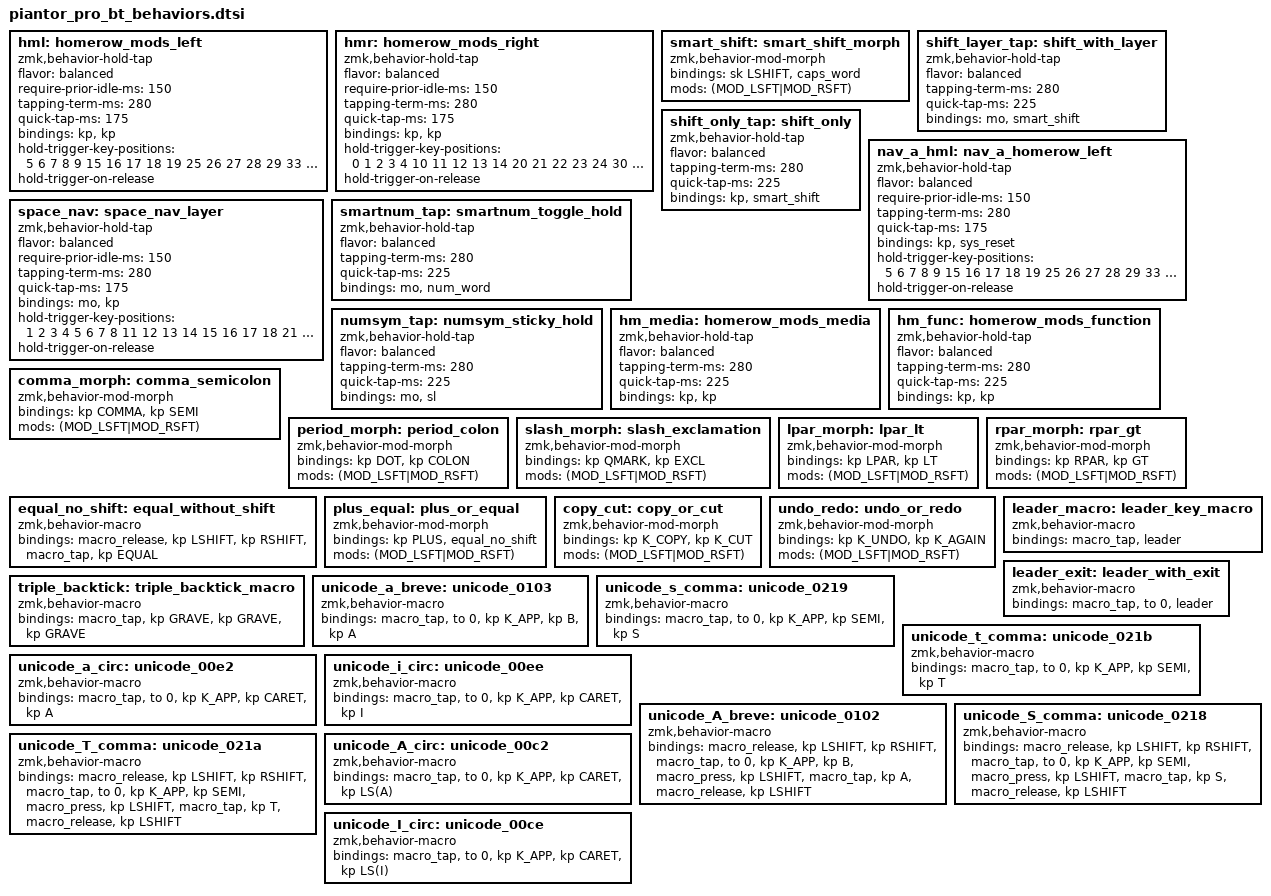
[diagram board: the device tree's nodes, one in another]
// Custom behaviors for Piantor Pro BT
hml: homerow_mods_left {
    compatible = "zmk,behavior-hold-tap";
    #binding-cells = <2>;
    flavor = "balanced";
    require-prior-idle-ms = <150>;
    tapping-term-ms = <280>;
    quick-tap-ms = <175>;
    bindings = <&kp>, <&kp>;
    hold-trigger-key-positions = <5 6 7 8 9 15 16 17 18 19 25 26 27 28 29 33 34 35>;
    hold-trigger-on-release;
};
hmr: homerow_mods_right {
    compatible = "zmk,behavior-hold-tap";
    #binding-cells = <2>;
    flavor = "balanced";
    require-prior-idle-ms = <150>;
    tapping-term-ms = <280>;
    quick-tap-ms = <175>;
    bindings = <&kp>, <&kp>;
    hold-trigger-key-positions = <0 1 2 3 4 10 11 12 13 14 20 21 22 23 24 30 31 32>;
    hold-trigger-on-release;
};
smart_shift: smart_shift_morph {
    compatible = "zmk,behavior-mod-morph";
    #binding-cells = <0>;
    bindings = <&sk LSHIFT>, <&caps_word>;
    mods = <(MOD_LSFT|MOD_RSFT)>;
};
shift_layer_tap: shift_with_layer {
    compatible = "zmk,behavior-hold-tap";
    #binding-cells = <2>;
    flavor = "balanced";
    tapping-term-ms = <280>;
    quick-tap-ms = <225>;
    bindings = <&mo>, <&smart_shift>;
};
shift_only_tap: shift_only {
    compatible = "zmk,behavior-hold-tap";
    #binding-cells = <2>;
    flavor = "balanced";
    tapping-term-ms = <280>;
    quick-tap-ms = <225>;
    bindings = <&kp>, <&smart_shift>;
};
// Nav layer position A: tap=reset, hold=alt (matches hml timing)
nav_a_hml: nav_a_homerow_left {
    compatible = "zmk,behavior-hold-tap";
    #binding-cells = <2>;
    flavor = "balanced";
    require-prior-idle-ms = <150>;
    tapping-term-ms = <280>;
    quick-tap-ms = <175>;
    bindings = <&kp>, <&sys_reset>;
    hold-trigger-key-positions = <5 6 7 8 9 15 16 17 18 19 25 26 27 28 29 33 34 35>;
    hold-trigger-on-release;
};
// Space nav layer: tap=space, hold=nav_sys layer (excludes dangerous positions)
space_nav: space_nav_layer {
    compatible = "zmk,behavior-hold-tap";
    #binding-cells = <2>;
    flavor = "balanced";
    require-prior-idle-ms = <150>;
    tapping-term-ms = <280>;
    quick-tap-ms = <175>;
    bindings = <&mo>, <&kp>;
    hold-trigger-key-positions = <1 2 3 4 5 6 7 8 11 12 13 14 15 16 17 18 21 22 23 24 25 26 27 28 30 31 32 33 34 35>;
    hold-trigger-on-release;
};
smartnum_tap: smartnum_toggle_hold {
    compatible = "zmk,behavior-hold-tap";
    #binding-cells = <2>;
    flavor = "balanced";
    tapping-term-ms = <280>;
    quick-tap-ms = <225>;
    bindings = <&mo>, <&num_word>;
};
numsym_tap: numsym_sticky_hold {
    compatible = "zmk,behavior-hold-tap";
    #binding-cells = <2>;
    flavor = "balanced";
    tapping-term-ms = <280>;
    quick-tap-ms = <225>;
    bindings = <&mo>, <&sl>;
};
#include "piantor_pro_bt_leader.dtsi"
// System layer media key home row mods
hm_media: homerow_mods_media {
    compatible = "zmk,behavior-hold-tap";
    #binding-cells = <2>;
    flavor = "balanced";
    tapping-term-ms = <280>;
    quick-tap-ms = <225>;
    bindings = <&kp>, <&kp>;
};
// System layer function key home row mods
hm_func: homerow_mods_function {
    compatible = "zmk,behavior-hold-tap";
    #binding-cells = <2>;
    flavor = "balanced";
    tapping-term-ms = <280>;
    quick-tap-ms = <225>;
    bindings = <&kp>, <&kp>;
};

// Custom shift behaviors for comma, period, slash
comma_morph: comma_semicolon {
    compatible = "zmk,behavior-mod-morph";
    #binding-cells = <0>;
    bindings = <&kp COMMA>, <&kp SEMI>;
    mods = <(MOD_LSFT|MOD_RSFT)>;
};
period_morph: period_colon {
    compatible = "zmk,behavior-mod-morph";
    #binding-cells = <0>;
    bindings = <&kp DOT>, <&kp COLON>;
    mods = <(MOD_LSFT|MOD_RSFT)>;
};
slash_morph: slash_exclamation {
    compatible = "zmk,behavior-mod-morph";
    #binding-cells = <0>;
    bindings = <&kp QMARK>, <&kp EXCL>;
    mods = <(MOD_LSFT|MOD_RSFT)>;
};
lpar_morph: lpar_lt {
    compatible = "zmk,behavior-mod-morph";
    #binding-cells = <0>;
    bindings = <&kp LPAR>, <&kp LT>;
    mods = <(MOD_LSFT|MOD_RSFT)>;
};
rpar_morph: rpar_gt {
    compatible = "zmk,behavior-mod-morph";
    #binding-cells = <0>;
    bindings = <&kp RPAR>, <&kp GT>;
    mods = <(MOD_LSFT|MOD_RSFT)>;
};
equal_no_shift: equal_without_shift {
    compatible = "zmk,behavior-macro";
    #binding-cells = <0>;
    bindings = <&macro_release &kp LSHIFT &kp RSHIFT>, <&macro_tap &kp EQUAL>;
};
plus_equal: plus_or_equal {
    compatible = "zmk,behavior-mod-morph";
    #binding-cells = <0>;
    bindings = <&kp PLUS>, <&equal_no_shift>;
    mods = <(MOD_LSFT|MOD_RSFT)>;
};
copy_cut: copy_or_cut {
    compatible = "zmk,behavior-mod-morph";
    #binding-cells = <0>;
    bindings = <&kp K_COPY>, <&kp K_CUT>;
    mods = <(MOD_LSFT|MOD_RSFT)>;
};
undo_redo: undo_or_redo {
    compatible = "zmk,behavior-mod-morph";
    #binding-cells = <0>;
    bindings = <&kp K_UNDO>, <&kp K_AGAIN>;
    mods = <(MOD_LSFT|MOD_RSFT)>;
};
leader_macro: leader_key_macro {
    compatible = "zmk,behavior-macro";
    #binding-cells = <0>;
    bindings = <&macro_tap &leader>;
};
leader_exit: leader_with_exit {
    compatible = "zmk,behavior-macro";
    #binding-cells = <0>;
    bindings = <&macro_tap &to 0 &leader>;
};
triple_backtick: triple_backtick_macro {
    compatible = "zmk,behavior-macro";
    #binding-cells = <0>;
    bindings = <&macro_tap &kp GRAVE &kp GRAVE &kp GRAVE>;
};

// Compose key macros for Romanian letters (faster than Unicode)
// Requires K_APPLICATION configured as compose key in Linux
unicode_a_breve: unicode_0103 {
    compatible = "zmk,behavior-macro";
    #binding-cells = <0>;
    bindings = <&macro_tap &to 0 &kp K_APP &kp B &kp A>;
};
unicode_s_comma: unicode_0219 {
    compatible = "zmk,behavior-macro";
    #binding-cells = <0>;
    bindings = <&macro_tap &to 0 &kp K_APP &kp SEMI &kp S>;
};
unicode_t_comma: unicode_021b {
    compatible = "zmk,behavior-macro";
    #binding-cells = <0>;
    bindings = <&macro_tap &to 0 &kp K_APP &kp SEMI &kp T>;
};
unicode_a_circ: unicode_00e2 {
    compatible = "zmk,behavior-macro";
    #binding-cells = <0>;
    bindings = <&macro_tap &to 0 &kp K_APP &kp CARET &kp A>;
};
unicode_i_circ: unicode_00ee {
    compatible = "zmk,behavior-macro";
    #binding-cells = <0>;
    bindings = <&macro_tap &to 0 &kp K_APP &kp CARET &kp I>;
};

// Compose key macros for capital Romanian letters
unicode_A_breve: unicode_0102 {
    compatible = "zmk,behavior-macro";
    #binding-cells = <0>;
    bindings = <&macro_release &kp LSHIFT &kp RSHIFT>
             , <&macro_tap &to 0 &kp K_APP &kp B>
             , <&macro_press &kp LSHIFT>
             , <&macro_tap &kp A>
             , <&macro_release &kp LSHIFT>;
};
unicode_S_comma: unicode_0218 {
    compatible = "zmk,behavior-macro";
    #binding-cells = <0>;
    bindings = <&macro_release &kp LSHIFT &kp RSHIFT>
             , <&macro_tap &to 0 &kp K_APP &kp SEMI>
             , <&macro_press &kp LSHIFT>
             , <&macro_tap &kp S>
             , <&macro_release &kp LSHIFT>;
};
unicode_T_comma: unicode_021a {
    compatible = "zmk,behavior-macro";
    #binding-cells = <0>;
    bindings = <&macro_release &kp LSHIFT &kp RSHIFT>
             , <&macro_tap &to 0 &kp K_APP &kp SEMI>
             , <&macro_press &kp LSHIFT>
             , <&macro_tap &kp T>
             , <&macro_release &kp LSHIFT>;
};
unicode_A_circ: unicode_00c2 {
    compatible = "zmk,behavior-macro";
    #binding-cells = <0>;
    bindings = <&macro_tap &to 0 &kp K_APP &kp CARET &kp LS(A)>;
};
unicode_I_circ: unicode_00ce {
    compatible = "zmk,behavior-macro";
    #binding-cells = <0>;
    bindings = <&macro_tap &to 0 &kp K_APP &kp CARET &kp LS(I)>;
};
